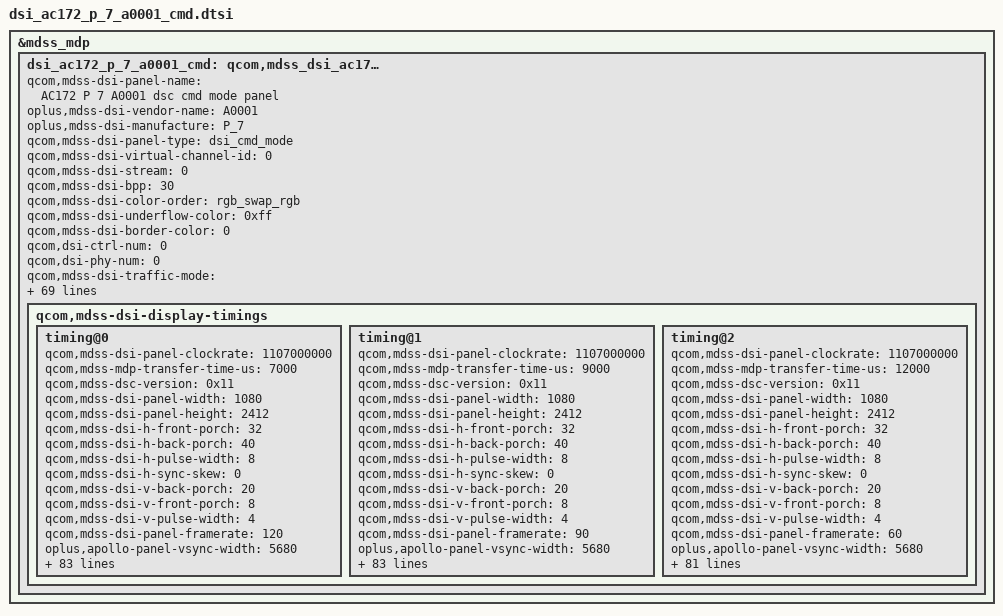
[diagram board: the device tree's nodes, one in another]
&mdss_mdp {
	dsi_ac172_p_7_a0001_cmd: qcom,mdss_dsi_ac172_p_7_a0001_cmd {
		qcom,mdss-dsi-panel-name = "AC172 P 7 A0001 dsc cmd mode panel";
		oplus,mdss-dsi-vendor-name = "A0001";
		oplus,mdss-dsi-manufacture = "P_7";
		qcom,mdss-dsi-panel-type = "dsi_cmd_mode";
		qcom,mdss-dsi-virtual-channel-id = <0>;
		qcom,mdss-dsi-stream = <0>;
		qcom,mdss-dsi-bpp = <30>;
		qcom,mdss-dsi-color-order = "rgb_swap_rgb";
		qcom,mdss-dsi-underflow-color = <0xff>;
		qcom,mdss-dsi-border-color = <0>;
		qcom,dsi-ctrl-num = <0>;
		qcom,dsi-phy-num = <0>;
		qcom,mdss-dsi-traffic-mode = "non_burst_sync_event";
		qcom,mdss-dsi-lane-map = "lane_map_0123";
		qcom,mdss-dsi-bllp-eof-power-mode;
		qcom,mdss-dsi-bllp-power-mode;
		qcom,mdss-dsi-lane-0-state;
		qcom,mdss-dsi-lane-1-state;
		qcom,mdss-dsi-lane-2-state;
		qcom,mdss-dsi-lane-3-state;
		qcom,mdss-dsi-dma-trigger = "trigger_sw";
		qcom,mdss-dsi-mdp-trigger = "none";
		qcom,mdss-dsi-bl-inverted-dbv;
		qcom,mdss-dsi-reset-sequence = <1 20>, <0 20>, <1 30>;
		qcom,mdss-dsi-te-pin-select = <1>;
		qcom,mdss-dsi-te-dcs-command = <1>;
		qcom,mdss-dsi-te-check-enable;
		qcom,mdss-dsi-te-using-te-pin;
		qcom,mdss-dsi-wr-mem-start = <0x2c>;
		qcom,mdss-dsi-wr-mem-continue = <0x3c>;
		qcom,mdss-dsi-panel-hdr-enabled;
		qcom,mdss-dsi-panel-hdr-color-primaries = <15000 15500 34000
			16000 13250 34500 7500 3000>;
		qcom,mdss-dsi-panel-peak-brightness = <4300000>;
		qcom,mdss-dsi-panel-blackness-level = <1023>;
		qcom,mdss-pan-physical-width-dimension = <70>;
		qcom,mdss-pan-physical-height-dimension = <155>;
		qcom,bl-update-flag = "delay_until_first_frame";

		qcom,mdss-dsi-display-timings {
			timing@0{
				qcom,mdss-dsi-panel-clockrate = <1107000000>;
				qcom,mdss-mdp-transfer-time-us = <7000>;
				qcom,mdss-dsc-version = <0x11>;
				qcom,mdss-dsi-panel-width = <1080>;
				qcom,mdss-dsi-panel-height = <2412>;
				qcom,mdss-dsi-h-front-porch = <32>;
				qcom,mdss-dsi-h-back-porch = <40>;
				qcom,mdss-dsi-h-pulse-width = <8>;
				qcom,mdss-dsi-h-sync-skew = <0>;
				qcom,mdss-dsi-v-back-porch = <20>;
				qcom,mdss-dsi-v-front-porch = <8>;
				qcom,mdss-dsi-v-pulse-width = <4>;
				qcom,mdss-dsi-panel-framerate = <120>;
				/* Apollo vsync config, need to measure TE signal */
				oplus,apollo-panel-vsync-width = <5680>;
				oplus,apollo-panel-vsync-period = <16850>;

				/* ofp config */
				oplus,ofp-need-to-sync-data-in-aod-unlocking;
				oplus,ofp-aod-off-insert-black-frame = <1>;
				oplus,ofp-aod-off-black-frame-total-time = <42>;
				oplus,ofp-need-to-separate-backlight;
				oplus,ofp-backlight-on-period = <1>;

				qcom,mdss-dsi-on-command = [
					39 01 00 00 00 00 05 FF AA 55 A5 81
					15 01 00 00 00 00 02 6F 24
					39 01 00 00 00 00 15 FB 00 03 04 55 77 77 77 99 9B 10 00 1E 48 9A BB BC DE F0 11 31

					/* Power on sequence optimize */
					39 01 00 00 00 00 05 FF AA 55 A5 83
					15 01 00 00 00 00 02 6F 12
					15 01 00 00 00 00 02 FE 41

					/* Waiting time for drawing */
					39 01 00 00 00 00 05 FF AA 55 A5 81
					15 01 00 00 00 00 02 6F 19
					15 01 00 00 00 00 02 FB 30

					/* Source waveform optimization */
					15 01 00 00 00 00 02 6F 05
					15 01 00 00 00 00 02 FE 3C
					39 01 00 00 00 00 06 F0 55 AA 52 08 06
					39 01 00 00 00 00 06 B2 00 38 37 37 37
					39 01 00 00 00 00 06 B3 37 38 38 38 38
					39 01 00 00 00 00 06 B8 00 38 37 37 37
					39 01 00 00 00 00 06 B9 37 38 38 38 38
					39 01 00 00 00 00 06 F0 55 AA 52 08 04
					15 01 00 00 00 00 02 EC E6
					15 01 00 00 00 00 02 6F 08
					39 01 00 00 00 00 03 B8 05 D6

					/* Idle no DMR */
					39 01 00 00 00 00 05 FF AA 55 A5 81
					15 01 00 00 00 00 02 6F 0E
					39 01 00 00 00 00 03 F5 2B 00

					/* Vesa for Idle */
					15 01 00 00 00 00 02 6F 02
					15 01 00 00 00 00 02 F9 04
					15 01 00 00 00 00 02 6F 0A
					15 01 00 00 00 00 02 FD 08

					/* AVC optimize */
					39 01 00 00 00 00 05 FF AA 55 A5 80
					15 01 00 00 00 00 02 6F 0F
					15 01 00 00 00 00 02 FC 00
					15 01 00 00 00 00 02 6F 09
					39 01 00 00 00 00 03 FC FC F0

					/* OSC1 = OSC2 =138.6M */
					39 01 00 00 00 00 05 FF AA 55 A5 80
					15 01 00 00 00 00 02 6F 15
					39 01 00 00 00 00 03 F8 01 7E
					15 01 00 00 00 00 02 6F 31
					39 01 00 00 00 00 03 F8 01 1E

					/* Gate waveform optimization */
					15 01 00 00 00 00 02 6F 19
					15 01 00 00 00 00 02 F2 00

					/* AOD timing optimization */
					15 01 00 00 00 00 02 6F 2D
					15 01 00 00 00 00 02 FC 44

					/* Power sequence adjust */
					15 01 00 00 00 00 02 6F 0A
					39 01 00 00 00 00 04 F6 70 70 70

					/* Power off sequence optimize */
					15 01 00 00 00 00 02 6F 0E
					15 01 00 00 00 00 02 F6 70

					/* AOD on/off Speed up */
					15 01 00 00 00 00 02 6F 2D
					15 01 00 00 00 00 02 FC 44

					/* SWC_ISOP,SWC_ISOPx=1 */
					39 01 00 00 00 00 05 FF AA 55 A5 80
					15 01 00 00 00 00 02 6F 1A
					15 01 00 00 00 00 02 F4 55

					/* Osc divider */
					15 01 00 00 00 00 02 6F 01
					15 01 00 00 00 00 02 1F 06

					/* DPC Temperature */
					39 01 00 00 00 00 03 81 01 19

					/* GIR OFF */
					15 01 00 00 00 00 02 5F 01

					/* Gamma Set */
					15 01 00 00 00 00 02 26 00

					/* Command Mode */
					15 01 00 00 00 00 02 17 10

					/* Set Column Address */
					39 01 00 00 00 00 05 2A 00 00 04 37

					/* Set Row Address */
					39 01 00 00 00 00 05 2B 00 00 09 6B

					/* 120Hz */
					15 01 00 00 00 00 02 2F 03

					/* TE On */
					15 01 00 00 00 00 02 35 00

					/* Manual TE */
					39 01 00 00 00 00 03 44 00 00

					/* BC Control Enable */
					15 01 00 00 00 00 02 53 20

					/* Vesa On */
					39 01 00 00 00 00 03 90 03 03

					/* PPS table 1 */
					39 01 00 00 00 00 13 91 AB 28 00 0C C2 00 02 0E 01 1F 00 07 08 BB 08 7A 10 F0
					05 01 00 00 78 00 01 11
					05 01 00 00 00 00 01 29

				];
				qcom,mdss-dsi-timing-switch-command = [
					/* 120hz Transition */
					15 01 00 00 00 00 02 2F 03
				];
				qcom,mdss-dsi-off-command = [
					05 01 00 00 0A 00 01 28
					05 01 00 00 78 00 01 10
				];
				qcom,mdss-dsi-lp1-command = [
					 /* AOD Lv Switch */
					15 00 00 40 00 00 02 6F 04
					39 00 00 40 00 00 03 51 02 FF
					 /* AOD on*/
					39 00 00 40 00 00 06 F0 55 AA 52 08 01
					15 00 00 40 00 00 02 6F 01
					15 00 00 40 00 00 02 D2 22
					15 00 00 40 00 00 01 39
					15 00 00 00 00 00 02 65 01
				];
				qcom,mdss-dsi-nolp-command = [
					15 00 00 40 00 00 02 65 00
					15 00 00 40 00 00 01 38
					39 00 00 00 00 00 03 51 00 00
				];
				qcom,mdss-dsi-aod-high-mode-command = [
					15 00 00 40 00 00 02 6F 04
					39 00 00 00 00 00 03 51 02 FF
				];
				qcom,mdss-dsi-aod-low-mode-command = [
					15 00 00 40 00 00 02 6F 04
					39 00 00 00 00 00 03 51 01 FF
				];
				qcom,mdss-dsi-hbm-on-command = [
					39 00 00 00 00 00 03 51 0F 01
				];
				qcom,mdss-dsi-hbm-off-command = [
					39 00 00 00 00 00 03 51 0D BB
				];
				qcom,mdss-dsi-demura-dbv-mode-0-command = [
					/* 0x1F5 > DBV >= 0x008 */
					39 00 00 40 00 00 06 F0 55 AA 52 08 00
					15 00 00 40 00 00 02 6F 2E
					39 00 00 40 00 00 04 C0 02 30 00
					39 00 00 40 00 00 06 F0 55 AA 52 08 04
					15 00 00 40 00 00 02 6F 01
					39 00 00 40 00 00 06 CB 05 0F 1F 7C E8
					15 00 00 40 00 00 02 6F 06
					39 00 00 40 00 00 0A CB 02 08 D1 57 22 6B 8D 52 BB
					39 00 00 40 00 00 06 F0 55 AA 52 08 04
					15 00 00 40 00 00 02 6F 02
					39 00 00 40 00 00 03 EC 9C DC
					15 00 00 40 00 00 02 6F A5
					39 00 00 40 00 00 07 EC 9C 9C 9C DC DC DC
					39 00 00 00 00 00 06 F0 55 AA 52 08 00
				];
				qcom,mdss-dsi-demura-dbv-mode-1-command = [
					/* 0x3F1 > DBV >= 0x1F6 */
					39 00 00 40 00 00 06 F0 55 AA 52 08 00
					15 00 00 40 00 00 02 6F 2E
					39 00 00 40 00 00 04 C0 02 30 00
					39 00 00 40 00 00 06 F0 55 AA 52 08 04
					15 00 00 40 00 00 02 6F 01
					39 00 00 40 00 00 06 CB 05 0F 1F 7C E8
					15 00 00 40 00 00 02 6F 06
					39 00 00 40 00 00 0A CB 02 08 D1 57 22 6B 8D 52 BB
					39 00 00 40 00 00 06 F0 55 AA 52 08 04
					15 00 00 40 00 00 02 6F 02
					39 00 00 40 00 00 03 EC 4C 8C
					15 00 00 40 00 00 02 6F A5
					39 00 00 40 00 00 07 EC 4C 4C 4C 8C 8C 8C
					39 00 00 00 00 00 06 F0 55 AA 52 08 00
				];
				qcom,mdss-dsi-demura-dbv-mode-2-command = [
					/* 0x561 > DBV >= 0x3F2 */
					39 00 00 40 00 00 06 F0 55 AA 52 08 00
					15 00 00 40 00 00 02 6F 2E
					39 00 00 40 00 00 04 C0 02 30 00
					39 00 00 40 00 00 06 F0 55 AA 52 08 04
					15 00 00 40 00 00 02 6F 01
					39 00 00 40 00 00 06 CB 05 0F 1F 7C E8
					15 00 00 40 00 00 02 6F 06
					39 00 00 40 00 00 0A CB 02 08 D1 57 22 6B 8D 52 BB
					39 00 00 40 00 00 06 F0 55 AA 52 08 04
					15 00 00 40 00 00 02 6F 02
					39 00 00 40 00 00 03 EC 10 50
					15 00 00 40 00 00 02 6F A5
					39 00 00 40 00 00 07 EC 10 10 10 50 50 50
					39 00 00 00 00 00 06 F0 55 AA 52 08 00
				];
				qcom,mdss-dsi-demura-dbv-mode-3-command = [
					/* 0xDBA > DBV >= 0x562 */
					39 00 00 40 00 00 06 F0 55 AA 52 08 00
					15 00 00 40 00 00 02 6F 2E
					39 00 00 40 00 00 04 C0 02 30 00
					39 00 00 40 00 00 06 F0 55 AA 52 08 04
					15 00 00 40 00 00 02 6F 01
					39 00 00 40 00 00 06 CB 05 0F 1F 7C E8
					15 00 00 40 00 00 02 6F 06
					39 00 00 40 00 00 0A CB 02 08 D1 57 22 6B 8D 52 BB
					39 00 00 40 00 00 06 F0 55 AA 52 08 04
					15 00 00 40 00 00 02 6F 02
					39 00 00 40 00 00 03 EC 03 05
					15 00 00 40 00 00 02 6F A5
					39 00 00 40 00 00 07 EC 03 03 03 05 05 05
					39 00 00 00 00 00 06 F0 55 AA 52 08 00
				];
				qcom,mdss-dsi-demura-dbv-mode-4-command = [
					/* 0xDBV > DBV >= 0xDBB */
					39 00 00 40 00 00 06 F0 55 AA 52 08 00
					15 00 00 40 00 00 02 6F 2E
					39 00 00 40 00 00 04 C0 15 40 00
					39 00 00 40 00 00 06 F0 55 AA 52 08 04
					15 00 00 40 00 00 02 6F 01
					39 00 00 40 00 00 06 CB 01 05 1F 7C E8
					15 00 00 40 00 00 02 6F 06
					39 00 00 40 00 00 0A CB 07 08 6B AD 28 BB EF A4 FE
					39 00 00 40 00 00 06 F0 55 AA 52 08 04
					15 00 00 40 00 00 02 6F 02
					39 00 00 40 00 00 03 EC 03 05
					15 00 00 40 00 00 02 6F A5
					39 00 00 40 00 00 07 EC 03 03 03 05 05 05
					39 00 00 00 00 00 06 F0 55 AA 52 08 00
				];

				qcom,mdss-dsi-aod-hbm-on-command-state = "dsi_lp_mode";
				qcom,mdss-dsi-aod-hbm-off-command-state = "dsi_lp_mode";
				qcom,mdss-dsi-hbm-on-command-state = "dsi_lp_mode";
				qcom,mdss-dsi-seed-off-command-state = "dsi_lp_mode";
				qcom,mdss-dsi-seed-0-command-state = "dsi_lp_mode";
				qcom,mdss-dsi-seed-1-command-state = "dsi_lp_mode";
				qcom,mdss-dsi-seed-2-command-state = "dsi_lp_mode";
				qcom,mdss-dsi-lp1-command-state = "dsi_lp_mode";
				qcom,mdss-dsi-aod-high-mode-command-state = "dsi_lp_mode";
				qcom,mdss-dsi-aod-low-mode-command-state = "dsi_lp_mode";
				qcom,mdss-dsi-nolp-command-state = "dsi_lp_mode";
				qcom,mdss-dsi-osc-clk-mode0-command-state = "dsi_lp_mode";
				qcom,mdss-dsi-osc-clk-mode1-command-state = "dsi_lp_mode";
				qcom,mdss-dsi-timing-switch-command-state = "dsi_lp_mode";
				qcom,mdss-dsi-on-command-state = "dsi_lp_mode";
				qcom,mdss-dsi-off-command-state = "dsi_lp_mode";
				qcom,mdss-dsi-demura-dbv-mode-0-command-state = "dsi_hs_mode";
				qcom,mdss-dsi-demura-dbv-mode-1-command-state = "dsi_hs_mode";
				qcom,mdss-dsi-demura-dbv-mode-2-command-state = "dsi_hs_mode";
				qcom,mdss-dsi-demura-dbv-mode-3-command-state = "dsi_hs_mode";
				qcom,mdss-dsi-demura-dbv-mode-4-command-state = "dsi_hs_mode";

				qcom,compression-mode = "dsc";
				qcom,mdss-dsc-slice-height = <12>;
				qcom,mdss-dsc-slice-width = <540>;
				qcom,mdss-dsc-slice-per-pkt = <2>;
				qcom,mdss-dsc-bit-per-component = <10>;
				qcom,mdss-dsc-bit-per-pixel = <8>;
				qcom,mdss-dsc-block-prediction-enable;
			};
			timing@1{
				qcom,mdss-dsi-panel-clockrate = <1107000000>;
				qcom,mdss-mdp-transfer-time-us = <9000>;
				qcom,mdss-dsc-version = <0x11>;
				qcom,mdss-dsi-panel-width = <1080>;
				qcom,mdss-dsi-panel-height = <2412>;
				qcom,mdss-dsi-h-front-porch = <32>;
				qcom,mdss-dsi-h-back-porch = <40>;
				qcom,mdss-dsi-h-pulse-width = <8>;
				qcom,mdss-dsi-h-sync-skew = <0>;
				qcom,mdss-dsi-v-back-porch = <20>;
				qcom,mdss-dsi-v-front-porch = <8>;
				qcom,mdss-dsi-v-pulse-width = <4>;
				qcom,mdss-dsi-panel-framerate = <90>;
				/* Apollo vsync config, need to measure TE signal */
				oplus,apollo-panel-vsync-width = <5680>;
				oplus,apollo-panel-vsync-period = <16850>;

				/* ofp config */
				oplus,ofp-need-to-sync-data-in-aod-unlocking;
				oplus,ofp-aod-off-insert-black-frame = <1>;
				oplus,ofp-aod-off-black-frame-total-time = <45>;
				oplus,ofp-need-to-separate-backlight;
				oplus,ofp-backlight-on-period = <1>;

				qcom,mdss-dsi-on-command = [
					39 01 00 00 00 00 05 FF AA 55 A5 81
					15 01 00 00 00 00 02 6F 24
					39 01 00 00 00 00 15 FB 00 03 04 55 77 77 77 99 9B 10 00 1E 48 9A BB BC DE F0 11 31

					/* Power on sequence optimize */
					39 01 00 00 00 00 05 FF AA 55 A5 83
					15 01 00 00 00 00 02 6F 12
					15 01 00 00 00 00 02 FE 41

					/* Waiting time for drawing */
					39 01 00 00 00 00 05 FF AA 55 A5 81
					15 01 00 00 00 00 02 6F 19
					15 01 00 00 00 00 02 FB 30

					/* Source waveform optimization */
					15 01 00 00 00 00 02 6F 05
					15 01 00 00 00 00 02 FE 3C
					39 01 00 00 00 00 06 F0 55 AA 52 08 06
					39 01 00 00 00 00 06 B2 00 38 37 37 37
					39 01 00 00 00 00 06 B3 37 38 38 38 38
					39 01 00 00 00 00 06 B8 00 38 37 37 37
					39 01 00 00 00 00 06 B9 37 38 38 38 38
					39 01 00 00 00 00 06 F0 55 AA 52 08 04
					15 01 00 00 00 00 02 EC E6
					15 01 00 00 00 00 02 6F 08
					39 01 00 00 00 00 03 B8 05 D6

					/* Idle no DMR */
					39 01 00 00 00 00 05 FF AA 55 A5 81
					15 01 00 00 00 00 02 6F 0E
					39 01 00 00 00 00 03 F5 2B 00

					/* Vesa for Idle */
					15 01 00 00 00 00 02 6F 02
					15 01 00 00 00 00 02 F9 04
					15 01 00 00 00 00 02 6F 0A
					15 01 00 00 00 00 02 FD 08

					/* AVC optimize */
					39 01 00 00 00 00 05 FF AA 55 A5 80
					15 01 00 00 00 00 02 6F 0F
					15 01 00 00 00 00 02 FC 00
					15 01 00 00 00 00 02 6F 09
					39 01 00 00 00 00 03 FC FC F0

					/* OSC1 = OSC2 =138.6M */
					39 01 00 00 00 00 05 FF AA 55 A5 80
					15 01 00 00 00 00 02 6F 15
					39 01 00 00 00 00 03 F8 01 7E
					15 01 00 00 00 00 02 6F 31
					39 01 00 00 00 00 03 F8 01 1E

					/* Gate waveform optimization */
					15 01 00 00 00 00 02 6F 19
					15 01 00 00 00 00 02 F2 00

					/* AOD timing optimization */
					15 01 00 00 00 00 02 6F 2D
					15 01 00 00 00 00 02 FC 44

					/* Power sequence adjust */
					15 01 00 00 00 00 02 6F 0A
					39 01 00 00 00 00 04 F6 70 70 70

					/* Power off sequence optimize */
					15 01 00 00 00 00 02 6F 0E
					15 01 00 00 00 00 02 F6 70

					/* AOD on/off Speed up */
					15 01 00 00 00 00 02 6F 2D
					15 01 00 00 00 00 02 FC 44

					/* SWC_ISOP,SWC_ISOPx=1 */
					39 01 00 00 00 00 05 FF AA 55 A5 80
					15 01 00 00 00 00 02 6F 1A
					15 01 00 00 00 00 02 F4 55

					/* Osc divider */
					15 01 00 00 00 00 02 6F 01
					15 01 00 00 00 00 02 1F 06

					/* DPC Temperature */
					39 01 00 00 00 00 03 81 01 19

					/* GIR OFF */
					15 01 00 00 00 00 02 5F 01

					/* Gamma Set */
					15 01 00 00 00 00 02 26 00

					/* Command Mode */
					15 01 00 00 00 00 02 17 10

					/* Set Column Address */
					39 01 00 00 00 00 05 2A 00 00 04 37

					/* Set Row Address */
					39 01 00 00 00 00 05 2B 00 00 09 6B

					/* 90Hz */
					15 01 00 00 00 00 02 2F 02

					/* TE On */
					15 01 00 00 00 00 02 35 00

					/* Manual TE */
					39 01 00 00 00 00 03 44 00 00

					/* BC Control Enable */
					15 01 00 00 00 00 02 53 20

					/* Vesa On */
					39 01 00 00 00 00 03 90 03 03

					/* PPS table 1 */
					39 01 00 00 00 00 13 91 AB 28 00 0C C2 00 02 0E 01 1F 00 07 08 BB 08 7A 10 F0
					05 01 00 00 78 00 01 11
					05 01 00 00 00 00 01 29

				];
				qcom,mdss-dsi-timing-switch-command = [
					/* 90hz Transition */
					15 01 00 00 00 00 02 2F 02
				];
				qcom,mdss-dsi-off-command = [
					05 01 00 00 0A 00 01 28
					05 01 00 00 78 00 01 10
				];
				qcom,mdss-dsi-lp1-command = [
					 /* AOD Lv Switch */
					15 00 00 40 00 00 02 6F 04
					39 00 00 40 00 00 03 51 02 FF
					 /* AOD on*/
					39 00 00 40 00 00 06 F0 55 AA 52 08 01
					15 00 00 40 00 00 02 6F 01
					15 00 00 40 00 00 02 D2 22
					15 00 00 40 00 00 01 39
					15 00 00 00 00 00 02 65 01
				];
				qcom,mdss-dsi-nolp-command = [
					15 00 00 40 00 00 02 65 00
					15 00 00 40 00 00 01 38
					39 00 00 00 00 00 03 51 00 00
				];
				qcom,mdss-dsi-aod-high-mode-command = [
					15 00 00 40 00 00 02 6F 04
					39 00 00 00 00 00 03 51 02 FF
				];
				qcom,mdss-dsi-aod-low-mode-command = [
					15 00 00 40 00 00 02 6F 04
					39 00 00 00 00 00 03 51 01 FF
				];
				qcom,mdss-dsi-hbm-on-command = [
					39 00 00 00 00 00 03 51 0F 01
				];
				qcom,mdss-dsi-hbm-off-command = [
					39 00 00 00 00 00 03 51 0D BB
				];
				qcom,mdss-dsi-demura-dbv-mode-0-command = [
					/* 0x1F5 > DBV >= 0x008 */
					39 00 00 40 00 00 06 F0 55 AA 52 08 00
					15 00 00 40 00 00 02 6F 2E
					39 00 00 40 00 00 04 C0 02 30 00
					39 00 00 40 00 00 06 F0 55 AA 52 08 04
					15 00 00 40 00 00 02 6F 01
					39 00 00 40 00 00 06 CB 05 0F 1F 7C E8
					15 00 00 40 00 00 02 6F 06
					39 00 00 40 00 00 0A CB 02 08 D1 57 22 6B 8D 52 BB
					39 00 00 40 00 00 06 F0 55 AA 52 08 04
					15 00 00 40 00 00 02 6F 02
					39 00 00 40 00 00 03 EC 9C DC
					15 00 00 40 00 00 02 6F A5
					39 00 00 40 00 00 07 EC 9C 9C 9C DC DC DC
					39 00 00 00 00 00 06 F0 55 AA 52 08 00
				];
				qcom,mdss-dsi-demura-dbv-mode-1-command = [
					/* 0x3F1 > DBV >= 0x1F6 */
					39 00 00 40 00 00 06 F0 55 AA 52 08 00
					15 00 00 40 00 00 02 6F 2E
					39 00 00 40 00 00 04 C0 02 30 00
					39 00 00 40 00 00 06 F0 55 AA 52 08 04
					15 00 00 40 00 00 02 6F 01
					39 00 00 40 00 00 06 CB 05 0F 1F 7C E8
					15 00 00 40 00 00 02 6F 06
					39 00 00 40 00 00 0A CB 02 08 D1 57 22 6B 8D 52 BB
					39 00 00 40 00 00 06 F0 55 AA 52 08 04
					15 00 00 40 00 00 02 6F 02
					39 00 00 40 00 00 03 EC 4C 8C
					15 00 00 40 00 00 02 6F A5
					39 00 00 40 00 00 07 EC 4C 4C 4C 8C 8C 8C
					39 00 00 00 00 00 06 F0 55 AA 52 08 00
				];
				qcom,mdss-dsi-demura-dbv-mode-2-command = [
					/* 0x561 > DBV >= 0x3F2 */
					39 00 00 40 00 00 06 F0 55 AA 52 08 00
					15 00 00 40 00 00 02 6F 2E
					39 00 00 40 00 00 04 C0 02 30 00
					39 00 00 40 00 00 06 F0 55 AA 52 08 04
					15 00 00 40 00 00 02 6F 01
					39 00 00 40 00 00 06 CB 05 0F 1F 7C E8
					15 00 00 40 00 00 02 6F 06
					39 00 00 40 00 00 0A CB 02 08 D1 57 22 6B 8D 52 BB
					39 00 00 40 00 00 06 F0 55 AA 52 08 04
					15 00 00 40 00 00 02 6F 02
					39 00 00 40 00 00 03 EC 10 50
					15 00 00 40 00 00 02 6F A5
					39 00 00 40 00 00 07 EC 10 10 10 50 50 50
					39 00 00 00 00 00 06 F0 55 AA 52 08 00
				];
				qcom,mdss-dsi-demura-dbv-mode-3-command = [
					/* 0xDBA > DBV >= 0x562 */
					39 00 00 40 00 00 06 F0 55 AA 52 08 00
					15 00 00 40 00 00 02 6F 2E
					39 00 00 40 00 00 04 C0 02 30 00
					39 00 00 40 00 00 06 F0 55 AA 52 08 04
					15 00 00 40 00 00 02 6F 01
					39 00 00 40 00 00 06 CB 05 0F 1F 7C E8
					15 00 00 40 00 00 02 6F 06
					39 00 00 40 00 00 0A CB 02 08 D1 57 22 6B 8D 52 BB
					39 00 00 40 00 00 06 F0 55 AA 52 08 04
					15 00 00 40 00 00 02 6F 02
					39 00 00 40 00 00 03 EC 03 05
					15 00 00 40 00 00 02 6F A5
					39 00 00 40 00 00 07 EC 03 03 03 05 05 05
					39 00 00 00 00 00 06 F0 55 AA 52 08 00
				];
				qcom,mdss-dsi-demura-dbv-mode-4-command = [
					/* 0xDBV > DBV >= 0xDBB */
					39 00 00 40 00 00 06 F0 55 AA 52 08 00
					15 00 00 40 00 00 02 6F 2E
					39 00 00 40 00 00 04 C0 15 40 00
					39 00 00 40 00 00 06 F0 55 AA 52 08 04
					15 00 00 40 00 00 02 6F 01
					39 00 00 40 00 00 06 CB 01 05 1F 7C E8
					15 00 00 40 00 00 02 6F 06
					39 00 00 40 00 00 0A CB 07 08 6B AD 28 BB EF A4 FE
					39 00 00 40 00 00 06 F0 55 AA 52 08 04
					15 00 00 40 00 00 02 6F 02
					39 00 00 40 00 00 03 EC 03 05
					15 00 00 40 00 00 02 6F A5
					39 00 00 40 00 00 07 EC 03 03 03 05 05 05
					39 00 00 00 00 00 06 F0 55 AA 52 08 00
				];

				qcom,mdss-dsi-aod-hbm-on-command-state = "dsi_lp_mode";
				qcom,mdss-dsi-aod-hbm-off-command-state = "dsi_lp_mode";
				qcom,mdss-dsi-hbm-on-command-state = "dsi_lp_mode";
				qcom,mdss-dsi-seed-off-command-state = "dsi_lp_mode";
				qcom,mdss-dsi-seed-0-command-state = "dsi_lp_mode";
				qcom,mdss-dsi-seed-1-command-state = "dsi_lp_mode";
				qcom,mdss-dsi-seed-2-command-state = "dsi_lp_mode";
				qcom,mdss-dsi-lp1-command-state = "dsi_lp_mode";
				qcom,mdss-dsi-aod-high-mode-command-state = "dsi_lp_mode";
				qcom,mdss-dsi-aod-low-mode-command-state = "dsi_lp_mode";
				qcom,mdss-dsi-nolp-command-state = "dsi_lp_mode";
				qcom,mdss-dsi-osc-clk-mode0-command-state = "dsi_lp_mode";
				qcom,mdss-dsi-osc-clk-mode1-command-state = "dsi_lp_mode";
				qcom,mdss-dsi-timing-switch-command-state = "dsi_lp_mode";
				qcom,mdss-dsi-on-command-state = "dsi_lp_mode";
				qcom,mdss-dsi-off-command-state = "dsi_lp_mode";
				qcom,mdss-dsi-demura-dbv-mode-0-command-state = "dsi_hs_mode";
				qcom,mdss-dsi-demura-dbv-mode-1-command-state = "dsi_hs_mode";
				qcom,mdss-dsi-demura-dbv-mode-2-command-state = "dsi_hs_mode";
				qcom,mdss-dsi-demura-dbv-mode-3-command-state = "dsi_hs_mode";
				qcom,mdss-dsi-demura-dbv-mode-4-command-state = "dsi_hs_mode";

				qcom,compression-mode = "dsc";
				qcom,mdss-dsc-slice-height = <12>;
				qcom,mdss-dsc-slice-width = <540>;
				qcom,mdss-dsc-slice-per-pkt = <2>;
				qcom,mdss-dsc-bit-per-component = <10>;
				qcom,mdss-dsc-bit-per-pixel = <8>;
				qcom,mdss-dsc-block-prediction-enable;
			};
			timing@2{
				qcom,mdss-dsi-panel-clockrate = <1107000000>;
				qcom,mdss-mdp-transfer-time-us = <12000>;
				qcom,mdss-dsc-version = <0x11>;
				qcom,mdss-dsi-panel-width = <1080>;
				qcom,mdss-dsi-panel-height = <2412>;
				qcom,mdss-dsi-h-front-porch = <32>;
				qcom,mdss-dsi-h-back-porch = <40>;
				qcom,mdss-dsi-h-pulse-width = <8>;
				qcom,mdss-dsi-h-sync-skew = <0>;
				qcom,mdss-dsi-v-back-porch = <20>;
				qcom,mdss-dsi-v-front-porch = <8>;
				qcom,mdss-dsi-v-pulse-width = <4>;
				qcom,mdss-dsi-panel-framerate = <60>;
				/* Apollo vsync config, need to measure TE signal */
				oplus,apollo-panel-vsync-width = <5680>;
				oplus,apollo-panel-vsync-period = <16850>;

				/* ofp config */
				oplus,ofp-need-to-sync-data-in-aod-unlocking;
				oplus,ofp-aod-off-insert-black-frame = <2>;
				oplus,ofp-aod-off-black-frame-total-time = <59>;
				oplus,ofp-need-to-separate-backlight;
				oplus,ofp-backlight-on-period = <1>;

				qcom,mdss-dsi-on-command = [
					39 01 00 00 00 00 05 FF AA 55 A5 81
					15 01 00 00 00 00 02 6F 24
					39 01 00 00 00 00 15 FB 00 03 04 55 77 77 77 99 9B 10 00 1E 48 9A BB BC DE F0 11 31

					/* Power on sequence optimize */
					39 01 00 00 00 00 05 FF AA 55 A5 83
					15 01 00 00 00 00 02 6F 12
					15 01 00 00 00 00 02 FE 41

					/* Waiting time for drawing */
					39 01 00 00 00 00 05 FF AA 55 A5 81
					15 01 00 00 00 00 02 6F 19
					15 01 00 00 00 00 02 FB 30

					/* Source waveform optimization */
					15 01 00 00 00 00 02 6F 05
					15 01 00 00 00 00 02 FE 3C
					39 01 00 00 00 00 06 F0 55 AA 52 08 06
					39 01 00 00 00 00 06 B2 00 38 37 37 37
					39 01 00 00 00 00 06 B3 37 38 38 38 38
					39 01 00 00 00 00 06 B8 00 38 37 37 37
					39 01 00 00 00 00 06 B9 37 38 38 38 38
					39 01 00 00 00 00 06 F0 55 AA 52 08 04
					15 01 00 00 00 00 02 EC E6
					15 01 00 00 00 00 02 6F 08
					39 01 00 00 00 00 03 B8 05 D6

					/* Idle no DMR */
					39 01 00 00 00 00 05 FF AA 55 A5 81
					15 01 00 00 00 00 02 6F 0E
					39 01 00 00 00 00 03 F5 2B 00

					/* Vesa for Idle */
					15 01 00 00 00 00 02 6F 02
					15 01 00 00 00 00 02 F9 04
					15 01 00 00 00 00 02 6F 0A
					15 01 00 00 00 00 02 FD 08

					/* AVC optimize */
					39 01 00 00 00 00 05 FF AA 55 A5 80
					15 01 00 00 00 00 02 6F 0F
					15 01 00 00 00 00 02 FC 00
					15 01 00 00 00 00 02 6F 09
					39 01 00 00 00 00 03 FC FC F0

					/* OSC1 = OSC2 =138.6M */
					39 01 00 00 00 00 05 FF AA 55 A5 80
					15 01 00 00 00 00 02 6F 15
					39 01 00 00 00 00 03 F8 01 7E
					15 01 00 00 00 00 02 6F 31
					39 01 00 00 00 00 03 F8 01 1E

					/* Gate waveform optimization */
					15 01 00 00 00 00 02 6F 19
					15 01 00 00 00 00 02 F2 00

					/* AOD timing optimization */
					15 01 00 00 00 00 02 6F 2D
					15 01 00 00 00 00 02 FC 44

					/* Power sequence adjust */
					15 01 00 00 00 00 02 6F 0A
					39 01 00 00 00 00 04 F6 70 70 70

					/* Power off sequence optimize */
					15 01 00 00 00 00 02 6F 0E
					15 01 00 00 00 00 02 F6 70

					/* AOD on/off Speed up */
					15 01 00 00 00 00 02 6F 2D
					15 01 00 00 00 00 02 FC 44

					/* SWC_ISOP,SWC_ISOPx=1 */
					39 01 00 00 00 00 05 FF AA 55 A5 80
					15 01 00 00 00 00 02 6F 1A
					15 01 00 00 00 00 02 F4 55

					/* Osc divider */
					15 01 00 00 00 00 02 6F 01
					15 01 00 00 00 00 02 1F 06

					/* DPC Temperature */
					39 01 00 00 00 00 03 81 01 19

					/* GIR OFF */
					15 01 00 00 00 00 02 5F 01

					/* Gamma Set */
					15 01 00 00 00 00 02 26 00

					/* Command Mode */
					15 01 00 00 00 00 02 17 10

					/* Set Column Address */
					39 01 00 00 00 00 05 2A 00 00 04 37

					/* Set Row Address */
					39 01 00 00 00 00 05 2B 00 00 09 6B

					/* 60Hz */
					15 01 00 00 00 00 02 2F 01

					/* TE On */
					15 01 00 00 00 00 02 35 00

					/* Manual TE */
					39 01 00 00 00 00 03 44 00 00

					/* BC Control Enable */
					15 01 00 00 00 00 02 53 20

					/* Vesa On */
					39 01 00 00 00 00 03 90 03 03

					/* PPS table 1 */
					39 01 00 00 00 00 13 91 AB 28 00 0C C2 00 02 0E 01 1F 00 07 08 BB 08 7A 10 F0
					05 01 00 00 78 00 01 11
					05 01 00 00 00 00 01 29

				];
				qcom,mdss-dsi-timing-switch-command = [
					/* 60Hz Transition */
					15 01 00 00 08 00 02 2F 01
				];
				qcom,mdss-dsi-off-command = [
					05 01 00 00 0A 00 01 28
					05 01 00 00 78 00 01 10
				];
				qcom,mdss-dsi-lp1-command = [
					 /* AOD Lv Switch */
					15 00 00 40 00 00 02 6F 04
					39 00 00 40 00 00 03 51 02 FF
					 /* AOD on*/
					39 00 00 40 00 00 06 F0 55 AA 52 08 01
					15 00 00 40 00 00 02 6F 01
					15 00 00 40 00 00 02 D2 22
					15 00 00 40 00 00 01 39
					15 00 00 00 00 00 02 65 01
				];
				qcom,mdss-dsi-nolp-command = [
					15 00 00 40 00 00 02 65 00
					15 00 00 40 00 00 01 38
					39 00 00 00 00 00 03 51 00 00
				];
				qcom,mdss-dsi-aod-high-mode-command = [
					15 00 00 40 00 00 02 6F 04
					39 00 00 00 00 00 03 51 02 FF
				];
				qcom,mdss-dsi-aod-low-mode-command = [
					15 00 00 40 00 00 02 6F 04
					39 00 00 00 00 00 03 51 01 FF
				];
				qcom,mdss-dsi-hbm-on-command = [
					39 00 00 00 00 00 03 51 0F 01
				];
				qcom,mdss-dsi-hbm-off-command = [
					39 00 00 00 00 00 03 51 0D BB
				];
				qcom,mdss-dsi-demura-dbv-mode-0-command = [
					/* 0x1F5 > DBV >= 0x008 */
					39 00 00 40 00 00 06 F0 55 AA 52 08 00
					15 00 00 40 00 00 02 6F 2E
					39 00 00 40 00 00 04 C0 02 30 00
					39 00 00 40 00 00 06 F0 55 AA 52 08 04
					15 00 00 40 00 00 02 6F 01
					39 00 00 40 00 00 06 CB 05 0F 1F 7C E8
					15 00 00 40 00 00 02 6F 06
					39 00 00 40 00 00 0A CB 02 08 D1 57 22 6B 8D 52 BB
					39 00 00 40 00 00 06 F0 55 AA 52 08 04
					15 00 00 40 00 00 02 6F 02
					39 00 00 40 00 00 03 EC 9C DC
					15 00 00 40 00 00 02 6F A5
					39 00 00 40 00 00 07 EC 9C 9C 9C DC DC DC
					39 00 00 00 00 00 06 F0 55 AA 52 08 00
				];
				qcom,mdss-dsi-demura-dbv-mode-1-command = [
					/* 0x3F1 > DBV >= 0x1F6 */
					39 00 00 40 00 00 06 F0 55 AA 52 08 00
					15 00 00 40 00 00 02 6F 2E
					39 00 00 40 00 00 04 C0 02 30 00
					39 00 00 40 00 00 06 F0 55 AA 52 08 04
					15 00 00 40 00 00 02 6F 01
					39 00 00 40 00 00 06 CB 05 0F 1F 7C E8
					15 00 00 40 00 00 02 6F 06
					39 00 00 40 00 00 0A CB 02 08 D1 57 22 6B 8D 52 BB
					39 00 00 40 00 00 06 F0 55 AA 52 08 04
					15 00 00 40 00 00 02 6F 02
					39 00 00 40 00 00 03 EC 4C 8C
					15 00 00 40 00 00 02 6F A5
					39 00 00 40 00 00 07 EC 4C 4C 4C 8C 8C 8C
					39 00 00 00 00 00 06 F0 55 AA 52 08 00
				];
				qcom,mdss-dsi-demura-dbv-mode-2-command = [
					/* 0x561 > DBV >= 0x3F2 */
					39 00 00 40 00 00 06 F0 55 AA 52 08 00
					15 00 00 40 00 00 02 6F 2E
					39 00 00 40 00 00 04 C0 02 30 00
					39 00 00 40 00 00 06 F0 55 AA 52 08 04
					15 00 00 40 00 00 02 6F 01
					39 00 00 40 00 00 06 CB 05 0F 1F 7C E8
					15 00 00 40 00 00 02 6F 06
					39 00 00 40 00 00 0A CB 02 08 D1 57 22 6B 8D 52 BB
					39 00 00 40 00 00 06 F0 55 AA 52 08 04
					15 00 00 40 00 00 02 6F 02
					39 00 00 40 00 00 03 EC 10 50
					15 00 00 40 00 00 02 6F A5
					39 00 00 40 00 00 07 EC 10 10 10 50 50 50
					39 00 00 00 00 00 06 F0 55 AA 52 08 00
				];
				qcom,mdss-dsi-demura-dbv-mode-3-command = [
					/* 0xDBA > DBV >= 0x562 */
					39 00 00 40 00 00 06 F0 55 AA 52 08 00
					15 00 00 40 00 00 02 6F 2E
					39 00 00 40 00 00 04 C0 02 30 00
					39 00 00 40 00 00 06 F0 55 AA 52 08 04
					15 00 00 40 00 00 02 6F 01
					39 00 00 40 00 00 06 CB 05 0F 1F 7C E8
					15 00 00 40 00 00 02 6F 06
					39 00 00 40 00 00 0A CB 02 08 D1 57 22 6B 8D 52 BB
					39 00 00 40 00 00 06 F0 55 AA 52 08 04
					15 00 00 40 00 00 02 6F 02
					39 00 00 40 00 00 03 EC 03 05
					15 00 00 40 00 00 02 6F A5
					39 00 00 40 00 00 07 EC 03 03 03 05 05 05
					39 00 00 00 00 00 06 F0 55 AA 52 08 00
				];
				qcom,mdss-dsi-demura-dbv-mode-4-command = [
					/* 0xDBV > DBV >= 0xDBB */
					39 00 00 40 00 00 06 F0 55 AA 52 08 00
					15 00 00 40 00 00 02 6F 2E
					39 00 00 40 00 00 04 C0 15 40 00
					39 00 00 40 00 00 06 F0 55 AA 52 08 04
					15 00 00 40 00 00 02 6F 01
					39 00 00 40 00 00 06 CB 01 05 1F 7C E8
					15 00 00 40 00 00 02 6F 06
					39 00 00 40 00 00 0A CB 07 08 6B AD 28 BB EF A4 FE
					39 00 00 40 00 00 06 F0 55 AA 52 08 04
					15 00 00 40 00 00 02 6F 02
					39 00 00 40 00 00 03 EC 03 05
					15 00 00 40 00 00 02 6F A5
					39 00 00 40 00 00 07 EC 03 03 03 05 05 05
					39 00 00 00 00 00 06 F0 55 AA 52 08 00
				];

				qcom,mdss-dsi-aod-hbm-on-command-state = "dsi_lp_mode";
				qcom,mdss-dsi-aod-hbm-off-command-state = "dsi_lp_mode";
				qcom,mdss-dsi-hbm-on-command-state = "dsi_lp_mode";
				qcom,mdss-dsi-seed-off-command-state = "dsi_lp_mode";
				qcom,mdss-dsi-seed-0-command-state = "dsi_lp_mode";
				qcom,mdss-dsi-seed-1-command-state = "dsi_lp_mode";
				qcom,mdss-dsi-seed-2-command-state = "dsi_lp_mode";
				qcom,mdss-dsi-lp1-command-state = "dsi_lp_mode";
				qcom,mdss-dsi-aod-high-mode-command-state = "dsi_lp_mode";
				qcom,mdss-dsi-aod-low-mode-command-state = "dsi_lp_mode";
				qcom,mdss-dsi-nolp-command-state = "dsi_lp_mode";
				qcom,mdss-dsi-osc-clk-mode0-command-state = "dsi_lp_mode";
				qcom,mdss-dsi-osc-clk-mode1-command-state = "dsi_lp_mode";
				qcom,mdss-dsi-on-command-state = "dsi_lp_mode";
				qcom,mdss-dsi-off-command-state = "dsi_lp_mode";
				qcom,mdss-dsi-demura-dbv-mode-0-command-state = "dsi_hs_mode";
				qcom,mdss-dsi-demura-dbv-mode-1-command-state = "dsi_hs_mode";
				qcom,mdss-dsi-demura-dbv-mode-2-command-state = "dsi_hs_mode";
				qcom,mdss-dsi-demura-dbv-mode-3-command-state = "dsi_hs_mode";
				qcom,mdss-dsi-demura-dbv-mode-4-command-state = "dsi_hs_mode";

				qcom,compression-mode = "dsc";
				qcom,mdss-dsc-slice-height = <12>;
				qcom,mdss-dsc-slice-width = <540>;
				qcom,mdss-dsc-slice-per-pkt = <2>;
				qcom,mdss-dsc-bit-per-component = <10>;
				qcom,mdss-dsc-bit-per-pixel = <8>;
				qcom,mdss-dsc-block-prediction-enable;
			};
		};
	};
};

&dsi_ac172_p_7_a0001_cmd {
	qcom,panel-supply-entries = <&Avatar_M_dsi_panel_pwr_supply_oled>;
	qcom,mdss-dsi-bl-pmic-control-type = "bl_ctrl_dcs";
	qcom,mdss-dsi-bl-min-level = <1>;
	qcom,mdss-dsi-bl-max-level = <4094>;
	qcom,mdss-brightness-max-level = <4094>;
	qcom,mdss-dsi-bl-hbm-min-level = <3327>;
	oplus,dsi-bl-normal-max-level = <3515>;
	oplus,dsi-brightness-normal-max-level = <3515>;
	oplus,dsi-brightness-default-level = <1843>;
	qcom,platform-te-gpio = <&tlmm 23 0>;
	qcom,platform-reset-gpio = <&tlmm 47 0>;
	qcom,platform-en-gpio = <&tlmm 101 0>;
	qcom,esd-check-enabled;
	qcom,mdss-dsi-panel-status-check-mode = "reg_read";
	qcom,mdss-dsi-panel-status-command = [
		06 01 00 00 00 00 01 0A
		06 00 00 00 00 00 01 91
		06 00 00 00 00 00 01 03
	];
	qcom,mdss-dsi-panel-status-command-state = "dsi_lp_mode";
	qcom,mdss-dsi-panel-status-value = <
		0x9C 0xAB 0x00
	>;
	qcom,mdss-dsi-panel-status-read-length = <1 1 1>;
	oplus,mdss-dsi-panel-status-match-modes = <0x00000000>;

	qcom,ulps-enabled;
	qcom,suspend-ulps-enabled;
	qcom,dsi-select-clocks = "pll_byte_clk0", "pll_dsi_clk0";

	/* ofp config */
	oplus,ofp-fp-type = <0x08>;
	oplus,ofp-need-to-wait-data-before-aod-on;

	/* demura dbv config */
	oplus,bl_denura-dbv-switch-support;

	oplus,dsi-serial-number-enabled;
	oplus,dsi-serial-number-index= <0>;
	oplus,dsi-serial-number-reg= <0xA3>;
	oplus,dsi-serial-number-read-count= <7>;

	qcom,mdss-dsi-display-timings {
		/* 120hz 553.5mhz */
		timing@0{
			qcom,mdss-dsi-panel-phy-timings = [00 24 0A 0A 1A 19 09 0A 09 02 04 00 1E 0F];
			qcom,display-topology = <1 1 1>;
			qcom,default-topology-index = <0>;
		};
		/* 90hz 553.5mhz */
		timing@1{
			qcom,mdss-dsi-panel-phy-timings = [00 24 0A 0A 1A 19 09 0A 09 02 04 00 1E 0F];
			qcom,display-topology = <1 1 1>;
			qcom,default-topology-index = <0>;
		};
		/* 60hz 553.5mhz */
		timing@2{
			qcom,mdss-dsi-panel-phy-timings = [00 24 0A 0A 1A 19 09 0A 09 02 04 00 1E 0F];
			qcom,display-topology = <1 1 1>;
			qcom,default-topology-index = <0>;
		};
	};
};

&dsi_ac172_p_7_a0001_cmd {
	qcom,panel_voltage_vddi_name = "vddi";
	qcom,panel_voltage_vddi = <0 1650000 1800000 1950000>;
	qcom,panel_voltage_vddr_name = "vddr";
	qcom,panel_voltage_vddr = <1 1450000 1500000 1600000>;
};
